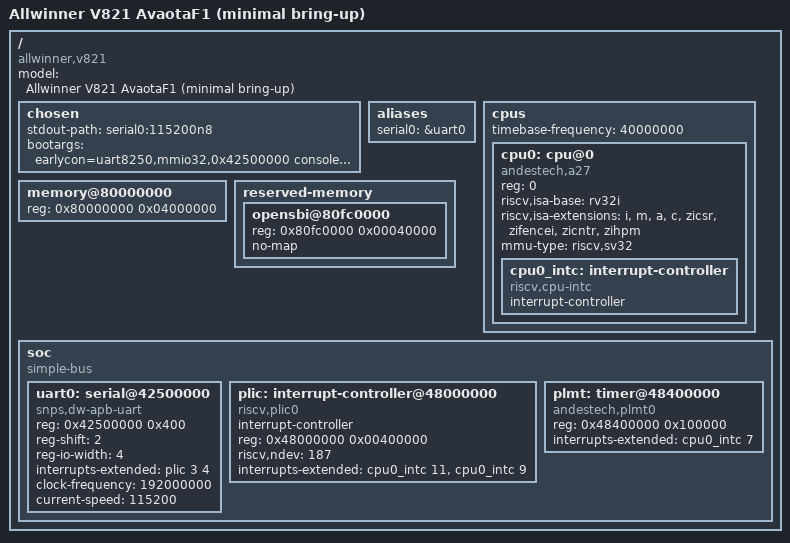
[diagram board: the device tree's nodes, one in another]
/dts-v1/;

/ {
	#address-cells = <1>;
	#size-cells = <1>;
	model = "Allwinner V821 AvaotaF1 (minimal bring-up)";
	compatible = "allwinner,v821", "allwinner,sun300iw1p1";

	chosen {
		stdout-path = "serial0:115200n8";
		/* The console drives the UART0 hardware directly (ttyS0), same as the
		 * factory kernel.
		 * earlycon uses uart8250,mmio32 with no baud, so it inherits the divisor
		 * the bootloader already programmed -> whatever clock-frequency says, no
		 * garbage on screen.
		 * Not hvc0/SBI console: two masters fighting over one UART corrupts the
		 * console, which is the real cause of the early [0.387] garbage -- not
		 * UART0 being unusable. */
		bootargs = "earlycon=uart8250,mmio32,0x42500000 console=ttyS0,115200 loglevel=8";
	};

	aliases {
		serial0 = &uart0;
	};

	cpus {
		#address-cells = <1>;
		#size-cells = <0>;
		timebase-frequency = <40000000>;	/* 40 MHz, from passed.dts */

		cpu0: cpu@0 {
			device_type = "cpu";
			reg = <0>;
			compatible = "andestech,a27", "riscv";
			/* The ISA uses the new interface only (riscv,isa-base plus
			 * riscv,isa-extensions); the deprecated riscv,isa is left out on
			 * purpose.
			 *
			 * Why that is safe: the kernel's riscv_early_of_processor_hartid()
			 * reads isa-base first and only falls through to old_interface when
			 * it is absent (c98f136aedbd). The new interface alone is enough.
			 *
			 * The cost (important): OpenSBI v1.4's fdt_parse_isa_all_harts()
			 * only understands the legacy property (fdt_helper.c:437), so this
			 * dts on v1.4 gives SBI_ENOENT -> generic_extensions_init() fails ->
			 * a silent hang in sbi_hart_hang() before the console is even up. To
			 * go back to v1.4, add riscv,isa = "rv32imac"; again. Upstream master
			 * (this repo's default) understands the new interface and is fine.
			 *
			 * Why there is no f/d: the A27 has an FPU, but userspace is
			 * soft-float (ilp32), and the FP save/restore path misbehaves on this
			 * core. Declaring rv32imac makes the kernel's has_fpu() false and
			 * turns __switch_to_fpu into a no-op, so not one FP instruction
			 * appears on the context-switch path.
			 * Note that initramfs/prebuilt/busybox is built for the same ABI --
			 * the two must agree, and a hard-float binary SIGILLs on the fsd in
			 * __sigsetjmp.
			 *
			 * zicsr/zifencei/zicntr/zihpm must be spelled out: the "i implies
			 * them" quirk (cpufeature.c:884) exists only on the legacy path, so
			 * the new interface has to list each one to be equivalent to
			 * rv32imac. */
			riscv,isa-base = "rv32i";
			riscv,isa-extensions = "i", "m", "a", "c",
					       "zicsr", "zifencei", "zicntr", "zihpm";
			mmu-type = "riscv,sv32";
			status = "okay";

			cpu0_intc: interrupt-controller {
				#interrupt-cells = <1>;
				interrupt-controller;
				compatible = "riscv,cpu-intc";
			};
		};
	};

	memory@80000000 {
		device_type = "memory";
		reg = <0x80000000 0x04000000>;	/* 64 MB */
	};

	reserved-memory {
		#address-cells = <1>;
		#size-cells = <1>;
		ranges;

		/* Reserved for the resident vendor OpenSBI region (factory boot.log:
		 * opensbi_base=0x80fc0000); 256 KB covers fw + heap + per-hart scratch.
		 *
		 * Note: on this repo's FEL path our own OpenSBI sits at 0x80000000 and
		 * this region is unused. It is kept because (a) the same dts can still be
		 * fed to the vendor boot chain, and (b) this is the memory layout that
		 * was verified booting, and dropping it would change a tested
		 * configuration for no gain. */
		opensbi@80fc0000 {
			reg = <0x80fc0000 0x00040000>;
			no-map;
		};
	};

	soc {
		#address-cells = <1>;
		#size-cells = <1>;
		compatible = "simple-bus";
		ranges;

		/* UART0: the kernel drives this hardware DIRECTLY (console=ttyS0),
		 * exactly like the factory Tina kernel (boot.log: "ttyS0 at MMIO
		 * 0x42500000"). Vendor OpenSBI's console is PASSIVE -- it only
		 * touches UART0 when the kernel makes an SBI console ecall -- so as
		 * long as our console is ttyS0 (not hvc0) and we never use the SBI
		 * console, OpenSBI does not contend for this UART. (The earlier
		 * "[0.387] garbage + reset" was self-inflicted: it ran earlycon=sbi/
		 * hvc0 AND the 8250 driver on UART0 at the same time.)
		 *   clock-frequency = 192 MHz: the UART ref clock is pll-peri-cko-192m
		 *     (PERI PLL 3072 MHz / 16); boot.log prints "uartclk 192000000"
		 *     and "base_baud = 12000000". 115200 divisor = 192e6/(16*115200)
		 *     = 104. (The old 24 MHz here was wrong -> 8x-too-fast garbage.)
		 * IRQ MODE: hwirq 3 comes from the vendor dtsi (sun300iw1p1.dtsi:496);
		 * PLIC #interrupt-cells = 2, so the cells are <hwirq,
		 * IRQ_TYPE_LEVEL_HIGH>. This line used to be commented out because the
		 * board reset on the first interactive RX -- but that was observed under
		 * the VENDOR OpenSBI, the same firmware behind the silent 62 s deadman,
		 * the fid-33 ebreak halt and the uncatchable CSR resets. On our own
		 * OpenSBI master with the A27 fixes (CLEAR_MDT/mstatush, CSR guards,
		 * delegation) the interrupt path is verified working: the boot line
		 * reports irq = 12, and the /proc/interrupts count for ttyS0 rises with
		 * typing (165 -> 452) with no reset. Both halves matter -- a non-zero irq
		 * = N only proves the DT property parsed and the PLIC domain mapped it,
		 * since a wrong hwirq prints a non-zero N too; the rising count is the
		 * one that needs the real wire.
		 * POLLED FALLBACK: if the reset ever comes back, comment this line out
		 * again -- the 8250 core then polls RX on a timer (irq=0): TX fine, RX
		 * with a few ms of latency, and no IRQ path at all. */
		uart0: serial@42500000 {
			compatible = "snps,dw-apb-uart";
			reg = <0x42500000 0x400>;
			reg-shift = <2>;
			reg-io-width = <4>;
			interrupts-extended = <&plic 3 4>;  // hwirq 3 from the vendor dtsi
			clock-frequency = <192000000>;	/* pll-peri-cko-192m; div=104 @115200 */
			current-speed = <115200>;
			status = "okay";
		};

		plic: interrupt-controller@48000000 {
			compatible = "riscv,plic0";	/* vendor passed.dts value */
			#address-cells = <0>;
			#interrupt-cells = <2>;
			interrupt-controller;
			reg = <0x48000000 0x00400000>;
			riscv,ndev = <187>;		/* 0xbb, from passed.dts */
			interrupts-extended = <&cpu0_intc 11>, <&cpu0_intc 9>;
		};

		/* Andes PLMT (Platform-Level Machine Timer): the RISC-V machine timer,
		 * mtime @ 0x48400000 (SUNXI_PLMT_BASE, from the SDK cpu_autogen.h).
		 * OpenSBI's andes_plmt / fdt_timer_plmt driver matches "andestech,plmt0"
		 * and uses it to back SBI set_timer. WITHOUT this the kernel finds no
		 * clocksource, falls back to "jiffies", gets no timer tick and hangs at
		 * cpuidle; WITH it the kernel gets riscv_clocksource and boots through. */
		plmt: timer@48400000 {
			compatible = "andestech,plmt0";
			reg = <0x48400000 0x100000>;
			interrupts-extended = <&cpu0_intc 7>;	/* hart0 M-timer (mtip) */
		};
	};
};
